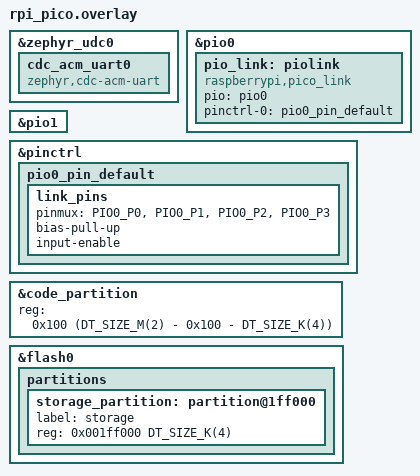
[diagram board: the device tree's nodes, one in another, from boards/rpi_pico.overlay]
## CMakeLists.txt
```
cmake_minimum_required(VERSION 3.20.0)

set(CMAKE_CXX_STANDARD 20)
set(CMAKE_CXX_STANDARD_REQUIRED ON)

# The following resolves the Zephyr location using the ZEPHYR_BASE environment variable.
# The `REQUIRED HINTS $ENV{ZEPHYR_BASE}` is optional in case you're not using `west zephyr-export`
# https://docs.zephyrproject.org/latest/develop/west/zephyr-cmds.html#installing-cmake-packages-west-zephyr-export

#set(ZEPHYR_MODULES "${CMAKE_SOURCE_DIR}/modules/hal/stm32" "${CMAKE_SOURCE_DIR}/modules/hal/cmsis")
set(ZEPHYR_MODULES "${CMAKE_SOURCE_DIR}/modules/hal/rpi_pico" "${CMAKE_SOURCE_DIR}/modules/hal/cmsis")

set(BOARD rpi_pico)

find_package(Zephyr REQUIRED HINTS "${CMAKE_SOURCE_DIR}/zephyr")


project(
    EmptyApp
    VERSION 0.1
    DESCRIPTION "Empty Zephyr application."
    LANGUAGES C
)

# The target "app" is defined in Zephyr's CMake package and is the default target for Zephyr apps.
target_sources(
    app
    PRIVATE
    src/main.cpp
)

set_compiler_property(PROPERTY diagnostic -fdiagnostics-color=never)


add_subdirectory(src/layers)
add_subdirectory(src/callbacks)
add_subdirectory(src/payloads)
add_subdirectory(src/sections)
add_subdirectory(src/module)
```

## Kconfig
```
mainmenu "GBLink Device Settings"
source "Kconfig.zephyr"

menu "Application Options"
    config SECTIONS_USE_MASTER_MODE
    bool "Use master mode to connect"
    default y
    help
        Use master mode to connect. 
        Disbale for slave mode to help debug slave setting
        WARNING for future Nils: This will probably not work since Game saves player under player ID which will swap if
        in next section device will switch to master. Why it works in "disconnect" is unkown, but probably due to slightly
        different code paths. To confirm see "DoesLinkPlayerCountMatchSaved" and change accordingly 

    config GB_LINK_MODE_ENABLED
    bool "Enable Game Boy link mode"
    default y
    help
        Enable support for Game Boy link communication.
        This adds the GB SPI passthrough and printer modes.

    config GB_LINK_DRIVE_SD_LOW
    bool "Drive SD pin LOW in GB link mode (generic GBC cable GBA support)"
    default n
    depends on GB_LINK_MODE_ENABLED
    help
        Drive the SD pin (pin 4 of the link connector) LOW whenever GB link
        mode is active.

        OEM GBC link cables leave pin 4 unconnected, so this has no effect
        on them. Generic GBC cables wire all 6 pins through, including pin 4,
        which means the SD signal actually reaches the GBA.

        The GBA reads SIOCNT bit 3 (SD state) to detect whether an external
        clock master is present. With SD floating HIGH (the default when this
        option is off) the GBA may not recognise the adapter as the master,
        causing GBA-mode transfers to fail. Driving SD LOW tells the GBA that
        an external device is driving the clock, which is the correct state
        when the adapter is acting as SPI master.

        Enable this option when using a generic GBC cable to connect to a GBA
        (e.g. for Gen 3 trading or multiboot). Safe to leave enabled even with
        OEM cables or original GB/GBC hardware — those devices either ignore
        the SD pin or treat SD LOW as a valid "external master" signal.

endmenu
```

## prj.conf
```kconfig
CONFIG_GPIO=y
CONFIG_DMA=y
CONFIG_COUNTER=y
CONFIG_EVENTS=y

CONFIG_SPEED_OPTIMIZATIONS=y

CONFIG_STDOUT_CONSOLE=y
CONFIG_USB_DEVICE_STACK=y
CONFIG_USB_DEVICE_BOS=y
CONFIG_USB_COMPOSITE_DEVICE=y
CONFIG_USB_CDC_ACM=y
# Composite (vendor + CDC) needs more concurrent transfers than the defaults.
CONFIG_USB_MAX_NUM_TRANSFERS=8
CONFIG_USB_NUMOF_EP_WRITE_RETRIES=10
CONFIG_SERIAL=y
CONFIG_USB_DEVICE_PRODUCT="GBLink USB"
CONFIG_USB_DEVICE_PID=0x000A
CONFIG_UART_INTERRUPT_DRIVEN=y
CONFIG_UART_LINE_CTRL=y
CONFIG_RING_BUFFER=y
CONFIG_USB_DEVICE_INITIALIZE_AT_BOOT=n

CONFIG_CPP=y
CONFIG_STD_CPP20=y
CONFIG_NEWLIB_LIBC=y
CONFIG_NEWLIB_LIBC_NANO=y
CONFIG_REQUIRES_FULL_LIBCPP=y

CONFIG_TICKLESS_KERNEL=y

CONFIG_THREAD_MONITOR=y
CONFIG_THREAD_NAME=y
CONFIG_DEBUG_THREAD_INFO=y
CONFIG_ASSERT=y

CONFIG_PINCTRL=y

# Flash storage for persistent settings (the WebUSB landing-page toggle).
CONFIG_FLASH=y
CONFIG_FLASH_MAP=y
CONFIG_FLASH_PAGE_LAYOUT=y

CONFIG_SECTIONS_USE_MASTER_MODE=y
CONFIG_REBOOT=y
# Driving SD low is opt-in (off by default). For rare compatibility issues with some GBAs.
CONFIG_GB_LINK_DRIVE_SD_LOW=n
```

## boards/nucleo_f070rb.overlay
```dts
#include <zephyr/dt-bindings/pinctrl/stm32-pinctrl.h>

&dma1 { 
    status = "okay";
};

&usb {
    pinctrl-0 = <&usb_dm_pa11 &usb_dp_pa12>;
	pinctrl-names = "default";
    status = "okay";
};

&timers16 {
    status = "okay";
    st,prescaler = <0x0F>;
    counter {
        status = "okay";
    };
};

&timers17 {
    status = "okay";
    st,prescaler = <0>;
    counter {
        status = "okay";
    };
};
```

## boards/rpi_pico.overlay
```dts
#include <zephyr/dt-bindings/pinctrl/rpi-pico-rp2040-pinctrl.h>

&zephyr_udc0 {
    cdc_acm_uart0: cdc_acm_uart0 {
        compatible = "zephyr,cdc-acm-uart";
    };
};

&pio0 {
    status = "okay";

    pio_link: piolink {
        compatible = "raspberrypi,pico_link";
        status = "okay";
        pio = <&pio0>;
        pinctrl-0 = <&pio0_pin_default>;
        pinctrl-names = "default";
    };
};

&pio1 {
    status = "okay";
};

&pinctrl {
    pio0_pin_default: pio0_pin_default {
        link_pins {
            pinmux = <PIO0_P0>, <PIO0_P1>, <PIO0_P2>, <PIO0_P3>;
            bias-pull-up;
            input-enable;
        };
    };
};

/*
 * Carve a 4 KB storage partition (one flash erase sector) off the top of flash
 * for persistent settings (URL toggle and LED customization). The application is
 * less than 200 KB and lives at the bottom, so the tail is free. The UF2 only writes
 * the app region, so this sector survives firmware updates.
 */
&code_partition {
    reg = <0x100 (DT_SIZE_M(2) - 0x100 - DT_SIZE_K(4))>;
};

&flash0 {
    partitions {
        storage_partition: partition@1ff000 {
            label = "storage";
            reg = <0x001ff000 DT_SIZE_K(4)>;
        };
    };
};
```

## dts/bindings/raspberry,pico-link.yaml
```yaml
# A YAML binding matching the node

compatible: "raspberrypi,pico_link"

include: [base.yaml, pinctrl-device.yaml]

properties:
  pio:
    type: phandle
    required: true
```

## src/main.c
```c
#include <zephyr/kernel.h>
#include <zephyr/irq.h>
#include <zephyr/drivers/uart.h>
#include <zephyr/drivers/gpio.h>

#include "./link/link.h"

#include "./payloads/linkPlayer.h"
#include "./payloads/trainerCard.h"

#include "./callbacks/blockCommand.h"
#include "./callbacks/emptyCommand.h"
#include "./callbacks/moveCommand.h"
#include "./callbacks/blockRequestCommand.h"
#include "./callbacks/readyExitStandbyCommand.h"

#include "link_defines.h"

typedef uint16_t (*TransmitHandler)();
static TransmitHandler g_transmitHandler = NULL;

static uint16_t g_receiveCommand[8] = {};
static struct k_sem g_command_semaphore;

static uint16_t crc_cb(uint16_t rx_bytes);

#define CMD_INDEX 0

bool blockRequest = false;

static uint8_t g_counter = 0;

bool runTransitionDoneCb = false;

void transiveDone_cb()
{
    if (!runTransitionDoneCb) return;
    g_counter++;

    if (g_counter == 8)
    {
        g_counter = 0;
        link_setTransiveCallback(crc_cb);
        k_sem_give(&g_command_semaphore);
    }
}

uint16_t command_cb(uint16_t rx_bytes)
{
    runTransitionDoneCb = true;
    g_receiveCommand[g_counter] = rx_bytes;
    
    if (g_transmitHandler == NULL) return 0x00;
    return g_transmitHandler();
}

uint16_t handshake_cb(uint16_t rx_bytes)
{
    runTransitionDoneCb = false;
    if (rx_bytes == LINK_MASTER_HANDSHAKE) 
    {
        link_setTransiveCallback(&crc_cb);
        return LINK_MASTER_HANDSHAKE;
    }
    
    return LINK_SLAVE_HANDSHAKE;
}

uint16_t crc_cb(uint16_t rx_bytes)
{
    runTransitionDoneCb = false;
    link_setTransiveCallback(command_cb);
    return rx_bytes;
}

int countTranmissions = false;
int counter = 0;
uint16_t mirror_cb(uint16_t rx_byte) {
    if (countTranmissions) counter++;
    if (counter >= 30) return 0x00;
    return rx_byte; 
}

bool send = false;
bool sendCard = false;
bool sendMovement = false;
bool chunkingDone = false;
uint16_t mirrorCounter = 0;

int main(void)
{
    link_setTransiveCallback(&handshake_cb);
    link_setTransiveDoneCallback(&transiveDone_cb);
    k_sem_init(&g_command_semaphore, 0, 1);

    while (1)
    {
        k_sem_take(&g_command_semaphore, K_FOREVER);
        if (chunkingDone)
        {
            chunkingDone = false;
            g_transmitHandler = emptyCommand_cb;
        }

        if (g_transmitHandler == readyExitStandbyCommand_cb)
        {
            g_transmitHandler = emptyCommand_cb;
        }

        if (g_transmitHandler == moveCommand_cb)
        {
            g_transmitHandler = emptyCommand_cb;
        }

        switch(g_receiveCommand[CMD_INDEX])
        {
            case LINKCMD_READY_CLOSE_LINK:
                link_setTransiveCallback(&handshake_cb);
                break;
            
            case LINKCMD_SEND_LINK_TYPE:
                if (g_receiveCommand[1] == LINKTYPE_TRADE_SETUP)
                {
                    const struct LinkPlayerBlock* linkPlayerBlock = linkPLayer();
                    blockCommandSetup(linkPlayerBlock, sizeof(*linkPlayerBlock), sizeof(*linkPlayerBlock));
                    g_transmitHandler = blockCommand_cb;
                }
                break;
        
            case LINKCMD_SEND_BLOCK_REQ:
                const struct TrainerCard* trainerCard = trainerCardPlaceholder();
                blockCommandSetup(trainerCard, sizeof(*trainerCard), 0x64);
                g_transmitHandler = blockCommand_cb;
                break;
            
            case LINKCMD_READY_EXIT_STANDBY:
                g_transmitHandler = readyExitStandbyCommand_cb;
                break;
            
            case LINKCMD_SEND_HELD_KEYS:
                g_transmitHandler = moveCommand_cb;
                break;
        }
        
        if (g_transmitHandler == blockCommand_cb)
        {
            chunkingDone = blockCommandChunk();
        }
        
    }

    return 0;
}
```

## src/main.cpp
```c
#include <zephyr/kernel.h>

#include "control.hpp"

#include "./layers/packetLayer.hpp"

#include "link_defines.h"

int main(void)
{
    Control g_control = Control();
    while (true)
    {
        g_control.executeMode();
    }

    return 0;
}
```

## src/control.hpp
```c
#include "layers/usbLayer.hpp"
#include "layers/serialLayer.hpp"
#include "layers/transport.hpp"
#include "layers/packetLayer.hpp"
#include "module/link.hpp"
#include "module/emu.hpp"
#include "module/gb.hpp"
#include "module/advanceWars.hpp"
#include "linkStatus.hpp"
#include "callbacks/commands.hpp"
#include "payloads/pokemon.hpp"
#include "module/moduleInterface.hpp"
#include "hardware.hpp"
#include "persist.hpp"

class Control
{
    enum class ControlCommand
    {
        SetMode = 0x00,
        Cancel = 0x01,
        EnterGBPrinter = 0x03,
        GetFirmwareInfo = 0x0F
    };

    // Firmware version: 2.1.2
    static constexpr uint8_t FW_VERSION_MAJOR = 2;
    static constexpr uint8_t FW_VERSION_MINOR = 1;
    static constexpr uint8_t FW_VERSION_PATCH = 2;

    enum class Mode
    {
        gbaTradeEmu = 0x00,
        gbaLink = 0x01,
        gbLink = 0x02,
        gbPrinter = 0x03,
        advanceWars = 0x04
    };

    static constexpr uint8_t callSetModeId = 0x01;

public:
    Control()
    {
        Transport::registerCommandHandler(receiveCommandHandler, this);

        k_sem_init(&m_waitForModeSemaphore, 0, 1);
    }

    void executeMode()
    {
        k_sem_take(&m_waitForModeSemaphore, K_FOREVER);
        // Capture the requested mode; callSetMode always sets m_mode before
        // giving the semaphore (including when preempting a running mode), so we
        // must not clobber it below. The variant travels with the mode.
        const Mode mode = m_mode;
        const uint8_t awVariant = m_awVariant;
        sendLinkStatus(LinkStatus::DeviceReady);

        switch (mode)
        {
            case Mode::gbaTradeEmu:
            {
                applyLedForSlot(LED_SLOT_GBA);
                link_detectCableType();

                party::partyInit();
                Transport::registerDataHandler(party::usbReceivePkmFile, nullptr);

                EmuModule emuModule;
                m_currentModule = &emuModule;
                emuModule.execute();

                sendLinkStatus(LinkStatus::EmuTradeSessionFinished);
                break;
            }

            case Mode::gbaLink:
            {
                applyLedForSlot(LED_SLOT_GBA);
                link_detectCableType();

                Transport::registerDataHandler(usbLink_receiveHandler, nullptr);

                LinkModule linkModule;
                m_currentModule = &linkModule;
                linkModule.execute();

                sendLinkStatus(LinkStatus::LinkClosed);
                break;
            }

            case Mode::gbLink:
            {
                GBModule gbModule;
                m_currentModule = &gbModule;
                gbModule.execute();  // Sets blue LED internally

                sendLinkStatus(LinkStatus::GBSessionFinished);
                break;
            }

            case Mode::gbPrinter:
            {
                GBModule gbModule;
                m_currentModule = &gbModule;
                gbModule.executePrinterMode();  // Sets purple LED internally

                sendLinkStatus(LinkStatus::GBSessionFinished);
                break;
            }

            case Mode::advanceWars:
            {
                applyLedForSlot(LED_SLOT_ADVANCE_WARS);
                link_detectCableType();

                Transport::registerDataHandler(awProto_receiveHandler, nullptr);

                AdvanceWarsModule advanceWarsModule(
                    awVariant == 2 ? awproto::GameVariant::aw2
                                   : awproto::GameVariant::aw1);
                m_currentModule = &advanceWarsModule;
                advanceWarsModule.execute();

                sendLinkStatus(LinkStatus::LinkClosed);
                break;
            }
        }

        m_currentModule = nullptr;
        applyLedForSlot(LED_SLOT_IDLE); // green = connected, no active mode
    }

private:
    struct k_sem m_waitForModeSemaphore;
    Mode m_mode;
    uint8_t m_awVariant = 0;

    IModule* m_currentModule = nullptr;

    bool canHandle(uint8_t command) { return (command & 0xF0) == 0x00; }

    // Hardware commands (0x40-0x4F) are device-level, handled regardless of active module
    bool isHardwareCommand(uint8_t command) { return (command & 0xF0) == 0x40; }

    enum class HardwareCommand : uint8_t
    {
        SetVoltage3V3 = 0x40,
        SetVoltage5V = 0x41,
        SetLEDColor = 0x42,
        RebootBootloader = 0x43,
        SetWebUsbLanding = 0x44,
        GetLedConfig = 0x45,
        SetModeLedColor = 0x46,
        ResetLedColors = 0x47,
        Reboot = 0x48,
    };

    void receiveCommand(std::span<const uint8_t> data)
    {
        if (data.empty()) return;

        // Handle hardware commands first (device-level, always available)
        if (isHardwareCommand(data[0]))
        {
            return handleHardwareCommand(data);
        }

        if (m_currentModule != nullptr && m_currentModule->canHandle(data[0]))
        {
            return m_currentModule->receiveCommand(data);
        } 
        
        if (!canHandle(data[0])) return;
        switch (static_cast<ControlCommand>(data[0]))
        {
            // Optional third byte selects a game variant within the mode
            // (Advance Wars: 1 = AW1, 2 = AW2; defaults to AW1 for older
            // clients that send only [command, mode]).
            case ControlCommand::SetMode:
                if (data.size() < 2) return;
                return callSetMode(static_cast<Mode>(data[1]),
                                   data.size() >= 3 ? data[2] : 0);
            case ControlCommand::Cancel: return callCancel();
            case ControlCommand::EnterGBPrinter: return callSetMode(Mode::gbPrinter);
            case ControlCommand::GetFirmwareInfo: return callGetFirmwareInfo();
            default: return;
        }
    }

    void handleHardwareCommand(std::span<const uint8_t> data)
    {
        switch (static_cast<HardwareCommand>(data[0]))
        {
            case HardwareCommand::SetVoltage3V3:
                Hardware::getInstance().setVoltage3V3();
                break;
            case HardwareCommand::SetVoltage5V:
                Hardware::getInstance().setVoltage5V();
                break;
            case HardwareCommand::SetLEDColor:
                if (data.size() >= 5) {
                    Hardware::getInstance().setLED(data[1], data[2], data[3], data[4] != 0);
                }
                break;
            case HardwareCommand::RebootBootloader:
                // Resets into the USB bootloader; does not return.
                Hardware::getInstance().rebootToBootloader();
                break;
            case HardwareCommand::SetWebUsbLanding:
                // Persist the WebUSB landing-page toggle; applies on next reconnect.
                if (data.size() >= 2) {
                    setLandingPageEnabled(data[1] != 0);
                }
                break;
            case HardwareCommand::GetLedConfig:
                return callGetLedConfig();
            case HardwareCommand::SetModeLedColor:
                // [0x46, slot, r, g, b] — persist a mode's LED colour.
                if (data.size() >= 5) {
                    setLedColor(data[1], data[2], data[3], data[4]);
                }
                break;
            case HardwareCommand::ResetLedColors:
                // Restore all per-mode LED colours to the built-in defaults.
                resetLedColors();
                break;
            case HardwareCommand::Reboot:
                // Warm-reboot into the app so persisted settings apply now; no return.
                Hardware::getInstance().reboot();
                break;
            default: break;
        }
    }

    void callGetLedConfig()
    {
        // [0x45, count, r0,g0,b0, ... r4,g4,b4]
        uint8_t info[2 + LED_SLOT_COUNT * 3];
        info[0] = static_cast<uint8_t>(HardwareCommand::GetLedConfig);
        info[1] = LED_SLOT_COUNT;
        for (uint8_t slot = 0; slot < LED_SLOT_COUNT; slot++) {
            getLedColor(slot, &info[2 + slot * 3]);
        }
        Transport::sendData(std::span<const uint8_t>(info, sizeof(info)));
    }

    //-////////////////////////////////////////////////////////////////////////////////////////////////////////-//
    // CALLS
    //-////////////////////////////////////////////////////////////////////////////////////////////////////////-//

    void callSetMode(Mode mode, uint8_t variant = 0)
    {
        m_mode = mode;
        m_awVariant = variant;
        // If a mode is already running, cancel it so executeMode unblocks and
        // switches to the new mode (otherwise SetMode would queue behind a mode
        // that never exits). Same cancel path the web "cancel" command uses.
        if (m_currentModule != nullptr)
        {
            m_currentModule->cancel();
        }
        k_sem_give(&m_waitForModeSemaphore);
    }

    void callCancel()
    {
        if (m_currentModule != nullptr) m_currentModule->cancel();
    }

    void callGetFirmwareInfo()
    {
        const uint8_t info[] = {
            0x0F, // Echo back the command ID so web app knows this is a firmware info response
            FW_VERSION_MAJOR,
            FW_VERSION_MINOR,
            FW_VERSION_PATCH,
            // Byte 4: WebUSB landing-page enabled (1) / disabled (0). Older web
            // apps simply ignore the extra byte.
            static_cast<uint8_t>(landingPageEnabled() ? 1 : 0)
        };
        Transport::sendData(std::span<const uint8_t>(info, sizeof(info)));
    }

    //-////////////////////////////////////////////////////////////////////////////////////////////////////////-//

    static void receiveCommandHandler(std::span<const uint8_t> receivedData, void* userData)
    {
        Control* self = static_cast<Control*>(userData);
        self->receiveCommand(receivedData);
    }
};
```

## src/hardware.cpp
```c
#include "hardware.hpp"

#include <zephyr/kernel.h>
#include <zephyr/sys/reboot.h>
#include "hardware/pio.h"
#include "hardware/gpio.h"
#include "hardware/clocks.h"
#include "hardware/timer.h"

extern "C" {
#include <zephyr/drivers/misc/pio_rpi_pico/pio_rpi_pico.h>
}

// --- Pin Definitions ---
#define WS2812_PIN      16
#define VSWITCH_3V3_PIN 11
#define VSWITCH_5V_PIN  12

// --- WS2812 PIO Program (4 instructions) ---
// Ported from gb-link-firmware-reconfigurable/main.c
static const uint16_t ws2812_program_instructions[] = {
    0x6221, //  0: out    x, 1       side 0 [2]
    0x1123, //  1: jmp    !x, 3      side 1 [1]
    0x1400, //  2: jmp    0          side 1 [4]
    0xa442, //  3: nop               side 0 [4]
};

static const struct pio_program ws2812_program = {
    .instructions = ws2812_program_instructions,
    .length = 4,
    .origin = -1,
};

// WS2812 uses pio1 (independent from link SPI on pio0)
static PIO g_ws2812_pio = NULL;
static uint g_ws2812_sm = 0;
static bool g_ws2812_initialized = false;

// --- Hardware Singleton ---

Hardware& Hardware::getInstance()
{
    static Hardware instance;
    return instance;
}

Hardware::Hardware()
{
    // Initialize voltage switching GPIOs (raw Pico SDK, matching linkLayer_pio.c pattern)
    gpio_init(VSWITCH_3V3_PIN);
    gpio_init(VSWITCH_5V_PIN);
    gpio_set_dir(VSWITCH_3V3_PIN, GPIO_OUT);
    gpio_set_dir(VSWITCH_5V_PIN, GPIO_OUT);

    // Safe state: both HIGH first
    gpio_put(VSWITCH_3V3_PIN, 1);
    gpio_put(VSWITCH_5V_PIN, 1);
    busy_wait_us(100);

    // Default to 3.3V mode
    gpio_put(VSWITCH_3V3_PIN, 0);

    // Initialize WS2812 NeoPixel
    ws2812Init();

    // Set initial LED to red (disconnected state)
    ws2812Set(0x000500); // GRB format: G=0x00, R=0x05, B=0x00
}

void Hardware::ws2812Init()
{
    // Pico SDK defines 'pio1' as a macro (pio1_hw) which breaks DT_NODELABEL.
    // Temporarily undefine it so device tree lookup works.
    #undef pio1
    const struct device* dev = DEVICE_DT_GET(DT_NODELABEL(pio1));
    if (!device_is_ready(dev)) {
        return;
    }

    g_ws2812_pio = pio_rpi_pico_get_pio(dev);
    pio_rpi_pico_allocate_sm(dev, &g_ws2812_sm);

    uint offset = pio_add_program(g_ws2812_pio, &ws2812_program);

    // Configure state machine for WS2812 protocol
    pio_gpio_init(g_ws2812_pio, WS2812_PIN);
    pio_sm_set_consecutive_pindirs(g_ws2812_pio, g_ws2812_sm, WS2812_PIN, 1, true);

    pio_sm_config c = pio_get_default_sm_config();
    sm_config_set_sideset(&c, 1, false, false);
    sm_config_set_sideset_pins(&c, WS2812_PIN);
    sm_config_set_out_shift(&c, false, true, 24);
    sm_config_set_fifo_join(&c, PIO_FIFO_JOIN_TX);
    sm_config_set_wrap(&c, offset, offset + 3);
    sm_config_set_clkdiv(&c, clock_get_hz(clk_sys) / (800000.0f * 8.0f));

    pio_sm_init(g_ws2812_pio, g_ws2812_sm, offset, &c);
    pio_sm_set_enabled(g_ws2812_pio, g_ws2812_sm, true);

    g_ws2812_initialized = true;
}

void Hardware::ws2812Set(uint32_t grb)
{
    if (!g_ws2812_initialized) return;
    pio_sm_put_blocking(g_ws2812_pio, g_ws2812_sm, grb << 8u);
}

// --- Public API ---

void Hardware::setVoltage3V3()
{
    // Both HIGH first (safe off), then pull 3.3V LOW
    gpio_put(VSWITCH_3V3_PIN, 1);
    gpio_put(VSWITCH_5V_PIN, 1);
    busy_wait_us(100);
    gpio_put(VSWITCH_3V3_PIN, 0);
}

void Hardware::setVoltage5V()
{
    // Both HIGH first (safe off), then pull 5V LOW
    gpio_put(VSWITCH_3V3_PIN, 1);
    gpio_put(VSWITCH_5V_PIN, 1);
    busy_wait_us(100);
    gpio_put(VSWITCH_5V_PIN, 0);
}

void Hardware::setLED(uint8_t r, uint8_t g, uint8_t b, bool on)
{
    if (on) {
        // NeoPixel expects GRB format
        uint32_t grb = ((uint32_t)g << 16) | ((uint32_t)r << 8) | b;
        ws2812Set(grb);
    } else {
        ws2812Set(0x000000);
    }
}

// Reset into the RP2040 USB bootloader (BOOTSEL/PICOBOOT) so the host can
// reflash over WebUSB. The Zephyr hal_rpi_pico module does not ship
// pico/bootrom.h, so look up reset_usb_boot() in the bootrom directly:
// the func-table pointer lives at 0x14 and the table-lookup routine at 0x18.
void Hardware::rebootToBootloader()
{
    typedef void *(*rom_table_lookup_fn)(uint16_t *table, uint32_t code);
    typedef void (*reset_usb_boot_fn)(uint32_t gpio_mask, uint32_t disable_mask);

    uint16_t *func_table = (uint16_t *)(uintptr_t)(*(uint16_t *)0x14);
    rom_table_lookup_fn rom_table_lookup =
        (rom_table_lookup_fn)(uintptr_t)(*(uint16_t *)0x18);

    const uint32_t reset_usb_boot_code = (uint32_t)('U' | ('B' << 8));
    reset_usb_boot_fn reset_usb_boot =
        (reset_usb_boot_fn)rom_table_lookup(func_table, reset_usb_boot_code);

    reset_usb_boot(0, 0); // does not return
}

// Warm-reboot back into the application (not the bootloader). Used to "apply now"
// after settings changes — persisted LED colours are re-read at boot.
void Hardware::reboot()
{
    sys_reboot(SYS_REBOOT_COLD); // does not return
}

// --- Boot-time Initialization ---
static int hardware_init()
{
    Hardware::getInstance();
    return 0;
}

SYS_INIT(hardware_init, APPLICATION, 0);
```

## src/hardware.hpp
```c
#pragma once

#include <cstdint>

class Hardware {
public:
    static Hardware& getInstance();

    Hardware(const Hardware&) = delete;
    Hardware& operator=(const Hardware&) = delete;
    Hardware(Hardware&&) = delete;
    Hardware& operator=(Hardware&&) = delete;

    void setVoltage3V3();
    void setVoltage5V();
    void setLED(uint8_t r, uint8_t g, uint8_t b, bool on);
    void rebootToBootloader();
    void reboot();

private:
    Hardware();
    void ws2812Init();
    void ws2812Set(uint32_t grb);
};
```

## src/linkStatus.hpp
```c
#include <zephyr/kernel.h>
#include "./layers/usbLayer.hpp"

#pragma once

enum class LinkStatus : uint16_t
{
    GameboyConnected = 0xFF00,
    GameboyDisconnected = 0xFF01,

    AwaitMode = 0xFF02,
    HandshakeReceived = 0xFF03,
    HandshakeFinished = 0xFF04,

    LinkConnected = 0xFF05,
    LinkReconnecting = 0xFF06,
    LinkClosed = 0xFF07,

    DeviceReady = 0xFF08,
    EmuTradeSessionFinished = 0xFF09,

    StatusDebug = 0xFFFF
};

inline bool sendLinkStatus(LinkStatus status)
{
    return UsbLayer::getInstance().sendStatus(std::span<const uint8_t, 2>(reinterpret_cast<const uint8_t*>(&status), 2));
}
```

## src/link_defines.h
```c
#define LINKCMD_BLENDER_STOP            0x1111
#define LINKCMD_SEND_LINK_TYPE          0x2222
#define LINKCMD_BLENDER_SCORE_MISS      0x2345
#define LINKCMD_READY_EXIT_STANDBY      0x2FFE
#define LINKCMD_SEND_PACKET             0x2FFF
#define LINKCMD_BLENDER_SEND_KEYS       0x4444
#define LINKCMD_BLENDER_SCORE_BEST      0x4523
#define LINKCMD_BLENDER_SCORE_GOOD      0x5432
#define LINKCMD_DUMMY_1                 0x5555
#define LINKCMD_DUMMY_2                 0x5566
#define LINKCMD_READY_CLOSE_LINK        0x5FFF
#define LINKCMD_SEND_EMPTY              0x6666
#define LINKCMD_SEND_0xEE               0x7777
#define LINKCMD_BLENDER_PLAY_AGAIN      0x7779
#define LINKCMD_COUNTDOWN               0x7FFF
#define LINKCMD_CONT_BLOCK              0x8888
#define LINKCMD_BLENDER_NO_BERRIES      0x9999
#define LINKCMD_BLENDER_NO_PBLOCK_SPACE 0xAAAA
#define LINKCMD_SEND_ITEM               0xAAAB
#define LINKCMD_READY_TO_TRADE          0xAABB
#define LINKCMD_READY_FINISH_TRADE      0xABCD
#define LINKCMD_INIT_BLOCK              0xBBBB
#define LINKCMD_READY_CANCEL_TRADE      0xBBCC
#define LINKCMD_SEND_HELD_KEYS          0xCAFE
#define LINKCMD_SEND_BLOCK_REQ          0xCCCC
#define LINKCMD_START_TRADE             0xCCDD
#define LINKCMD_CONFIRM_FINISH_TRADE    0xDCBA
#define LINKCMD_SET_MONS_TO_TRADE       0xDDDD
#define LINKCMD_PLAYER_CANCEL_TRADE     0xDDEE
#define LINKCMD_REQUEST_CANCEL          0xEEAA
#define LINKCMD_BOTH_CANCEL_TRADE       0xEEBB
#define LINKCMD_PARTNER_CANCEL_TRADE    0xEECC
#define LINKCMD_NONE                    0xEFFF

#define LINKCMD_EMPTY                   0x0000

#define LINKTYPE_TRADE               0x1111
#define LINKTYPE_TRADE_CONNECTING    0x1122
#define LINKTYPE_TRADE_SETUP         0x1133
#define LINKTYPE_TRADE_DISCONNECTED  0x1144
#define LINKTYPE_BATTLE              0x2211
#define LINKTYPE_UNUSED_BATTLE       0x2222 // Unused, inferred from gap
#define LINKTYPE_SINGLE_BATTLE       0x2233
#define LINKTYPE_DOUBLE_BATTLE       0x2244
#define LINKTYPE_MULTI_BATTLE        0x2255
#define LINKTYPE_BATTLE_TOWER_50     0x2266
#define LINKTYPE_BATTLE_TOWER_OPEN   0x2277
#define LINKTYPE_BATTLE_TOWER        0x2288
#define LINKTYPE_RECORD_MIX_BEFORE   0x3311
#define LINKTYPE_RECORD_MIX_AFTER    0x3322
#define LINKTYPE_BERRY_BLENDER_SETUP 0x4411
#define LINKTYPE_BERRY_BLENDER       0x4422
#define LINKTYPE_MYSTERY_EVENT       0x5501
#define LINKTYPE_EREADER_FRLG        0x5502
#define LINKTYPE_EREADER_EM          0x5503
#define LINKTYPE_CONTEST_GMODE       0x6601
#define LINKTYPE_CONTEST_EMODE       0x6602

#define LINK_PLAYER_ID              0x81

#define LINK_MASTER_HANDSHAKE       0x8FFF
#define LINK_SLAVE_HANDSHAKE        0xB9A0
#define LINK_HANDSHAKE_DISABLE      0xD15E
```

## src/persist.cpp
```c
#include "persist.hpp"
#include "hardware.hpp"

#include <cstring>
#include <zephyr/storage/flash_map.h>

namespace
{
    #define STORAGE_PARTITION_ID FIXED_PARTITION_ID(storage_partition)

    constexpr uint8_t SETTINGS_MAGIC = 0x5A;
    constexpr uint8_t SETTINGS_VERSION = 4; // bumped to re-default the LED colours

    struct PersistSettings
    {
        uint8_t magic;
        uint8_t version;
        uint8_t landing;                       // 0 = disabled, else enabled
        uint8_t led[LED_SLOT_COUNT][3];        // per-slot logical RGB
    };

    // Real-colour defaults at a uniform 50% brightness (128/255) so every mode's
    // brightness slider starts at the same place. WS2812 magnitude = brightness.
    const uint8_t kDefaultColors[LED_SLOT_COUNT][3] = {
        { 0,   128, 0   }, // idle/connected — green
        { 128, 128, 0   }, // GBA/Celio — yellow
        { 0,   0,   128 }, // GB/GBC — blue
        { 128, 0,   128 }, // printer — purple
        { 0,   128, 128 }, // Advance Wars — cyan
    };

    void fillDefaults(PersistSettings& s)
    {
        s.magic = SETTINGS_MAGIC;
        s.version = SETTINGS_VERSION;
        s.landing = 1;
        memcpy(s.led, kDefaultColors, sizeof(s.led));
    }

    // Load the settings struct, falling back to defaults when flash is unwritten
    // or from an older layout (magic/version mismatch).
    PersistSettings loadSettings()
    {
        PersistSettings s{};
        const struct flash_area *fa;
        if (flash_area_open(STORAGE_PARTITION_ID, &fa) != 0) {
            fillDefaults(s);
            return s;
        }
        flash_area_read(fa, 0, &s, sizeof(s));
        flash_area_close(fa);

        if (s.magic != SETTINGS_MAGIC || s.version != SETTINGS_VERSION) {
            fillDefaults(s);
        }
        return s;
    }

    void saveSettings(const PersistSettings& s)
    {
        const struct flash_area *fa;
        if (flash_area_open(STORAGE_PARTITION_ID, &fa) != 0) {
            return;
        }
        // Flash must be erased before writing; RP2040 write-block-size is 1.
        flash_area_erase(fa, 0, fa->fa_size);
        flash_area_write(fa, 0, &s, sizeof(s));
        flash_area_close(fa);
    }
}

bool landingPageEnabled()
{
    return loadSettings().landing != 0;
}

void setLandingPageEnabled(bool enabled)
{
    PersistSettings s = loadSettings();
    s.landing = enabled ? 1 : 0;
    saveSettings(s);
}

void getLedColor(uint8_t slot, uint8_t out[3])
{
    if (slot >= LED_SLOT_COUNT) { out[0] = out[1] = out[2] = 0; return; }
    PersistSettings s = loadSettings();
    out[0] = s.led[slot][0];
    out[1] = s.led[slot][1];
    out[2] = s.led[slot][2];
}

void setLedColor(uint8_t slot, uint8_t r, uint8_t g, uint8_t b)
{
    if (slot >= LED_SLOT_COUNT) return;
    PersistSettings s = loadSettings();
    s.led[slot][0] = r;
    s.led[slot][1] = g;
    s.led[slot][2] = b;
    saveSettings(s);
}

void resetLedColors()
{
    PersistSettings s = loadSettings();
    memcpy(s.led, kDefaultColors, sizeof(s.led));
    saveSettings(s);
}

void applyLedForSlot(uint8_t slot)
{
    uint8_t c[3];
    getLedColor(slot, c);
    Hardware::getInstance().setLED(c[0], c[1], c[2], true);
}
```

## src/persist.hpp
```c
#pragma once

#include <cstdint>

// Persistent device settings, stored in the dedicated 4 KB flash "storage"
// partition (see boards/rpi_pico.overlay). One versioned struct holds the
// WebUSB landing-page flag and the per-mode LED colors.

// Per-mode LED colour slots (fixed order — shared with the launcher UI).
enum LedSlot : uint8_t {
    LED_SLOT_IDLE = 0,        // connected, no active mode (green)
    LED_SLOT_GBA = 1,         // GBA trade/link (yellow)
    LED_SLOT_GBC = 2,         // GB/GBC link (blue)
    LED_SLOT_PRINTER = 3,     // GB printer (purple)
    LED_SLOT_ADVANCE_WARS = 4,// Advance Wars (cyan)
    LED_SLOT_COUNT = 5,
};

// WebUSB landing-page advertising. Default (unwritten flash) is enabled.
bool landingPageEnabled();
void setLandingPageEnabled(bool enabled);

// Per-mode LED colours (logical RGB, 0-255; the WS2812 driver does GRB packing).
void getLedColor(uint8_t slot, uint8_t out[3]);
void setLedColor(uint8_t slot, uint8_t r, uint8_t g, uint8_t b);
void resetLedColors(); // restore all slots to the built-in defaults

// Apply a slot's stored colour to the LED now (used at mode entry).
void applyLedForSlot(uint8_t slot);
```
